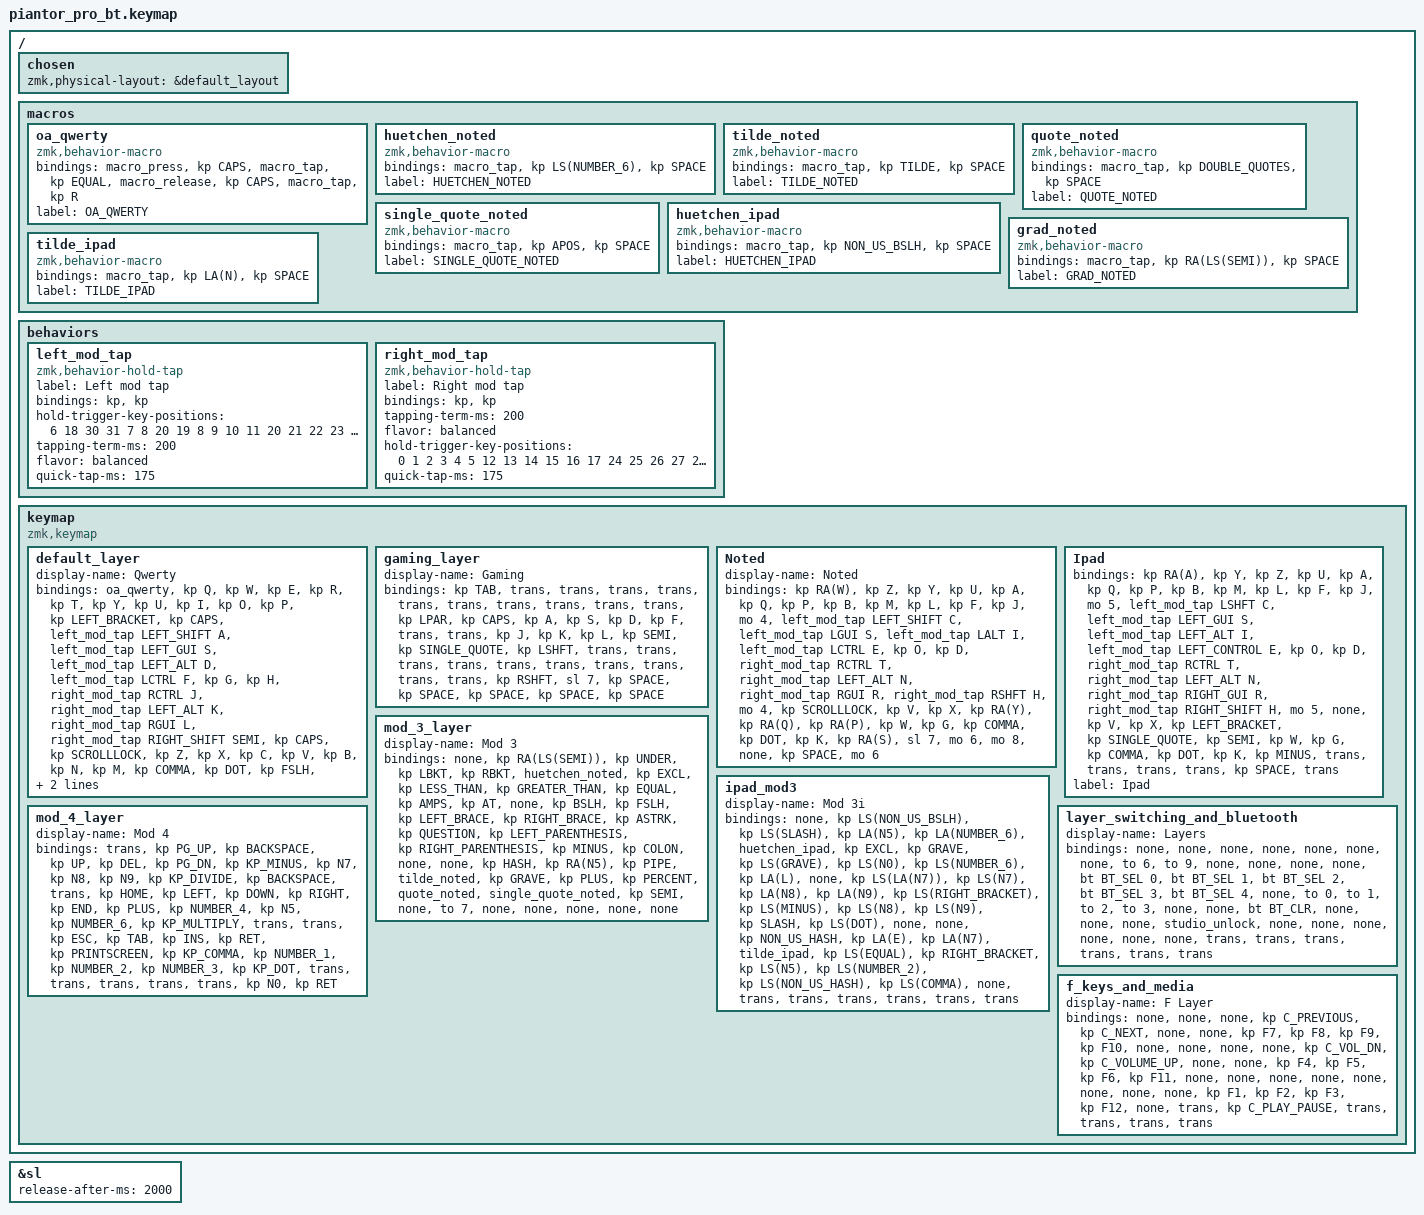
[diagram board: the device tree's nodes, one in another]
/*
 * Copyright (c) 2020 The ZMK Contributors
 *
 * SPDX-License-Identifier: MIT
 */

#include <behaviors.dtsi>
#include <dt-bindings/zmk/bt.h>
#include <dt-bindings/zmk/keys.h>

&sl {
    release-after-ms = <2000>;

    /delete-property/ quick-release;
};

/ {
    chosen { zmk,physical-layout = &default_layout; };
};

/ {
    macros {
        oa_qwerty: oa_qwerty {
            compatible = "zmk,behavior-macro";
            #binding-cells = <0>;
            bindings =
                <&macro_press>,
                <&kp CAPS>,
                <&macro_tap>,
                <&kp EQUAL>,
                <&macro_release>,
                <&kp CAPS>,
                <&macro_tap>,
                <&kp R>;

            label = "OA_QWERTY";
        };

        huetchen_noted: huetchen_noted {
            compatible = "zmk,behavior-macro";
            #binding-cells = <0>;
            bindings = <&macro_tap>, <&kp LS(NUMBER_6) &kp SPACE>;

            label = "HUETCHEN_NOTED";
        };

        tilde_noted: tilde_noted {
            compatible = "zmk,behavior-macro";
            #binding-cells = <0>;
            bindings = <&macro_tap>, <&kp TILDE &kp SPACE>;

            label = "TILDE_NOTED";
        };

        quote_noted: quote_noted {
            compatible = "zmk,behavior-macro";
            #binding-cells = <0>;
            bindings = <&macro_tap>, <&kp DOUBLE_QUOTES &kp SPACE>;

            label = "QUOTE_NOTED";
        };

        single_quote_noted: single_quote_noted {
            compatible = "zmk,behavior-macro";
            #binding-cells = <0>;
            bindings = <&macro_tap>, <&kp APOS &kp SPACE>;

            label = "SINGLE_QUOTE_NOTED";
        };

        huetchen_ipad: huetchen_ipad {
            compatible = "zmk,behavior-macro";
            #binding-cells = <0>;
            bindings = <&macro_tap>, <&kp NON_US_BSLH &kp SPACE>;

            label = "HUETCHEN_IPAD";
        };

        grad_noted: grad_noted {
            compatible = "zmk,behavior-macro";
            #binding-cells = <0>;
            bindings = <&macro_tap>, <&kp RA(LS(SEMI)) &kp SPACE>;

            label = "GRAD_NOTED";
        };

        tilde_ipad: tilde_ipad {
            compatible = "zmk,behavior-macro";
            #binding-cells = <0>;
            bindings = <&macro_tap>, <&kp LA(N) &kp SPACE>;

            label = "TILDE_IPAD";
        };
    };

    behaviors {
        left_mod_tap: left_mod_tap {
            compatible = "zmk,behavior-hold-tap";
            label = "Left mod tap";
            bindings = <&kp>, <&kp>;

            #binding-cells = <2>;
            hold-trigger-key-positions = <6 18 30 31 7 8 20 19 8 9 10 11 20 21 22 23 32 33 35 34 39 40 41 38 37 36>;
            tapping-term-ms = <200>;
            flavor = "balanced";
            quick-tap-ms = <175>;
        };

        right_mod_tap: right_mod_tap {
            compatible = "zmk,behavior-hold-tap";
            label = "Right mod tap";
            bindings = <&kp>, <&kp>;

            #binding-cells = <2>;
            tapping-term-ms = <200>;
            flavor = "balanced";
            hold-trigger-key-positions = <0 1 2 3 4 5 12 13 14 15 16 17 24 25 26 27 28 29 36 37 38 40 39 41>;
            quick-tap-ms = <175>;
        };
    };

    keymap {
        compatible = "zmk,keymap";

        default_layer {
            display-name = "Qwerty";

            // --------------------------------------------------------------------------------
            // |  TAB |  Q  |  W  |  E  |  R  |  T  |  Y  |  U   |  I  |  O  |  P  | BSPC |
            // | CTRL |  A  |  S  |  D  |  F  |  G  |  H  |  J   |  K  |  L  |  ;  |  '   |
            // | SHFT |  Z  |  X  |  C  |  V  |  B  |  N  |  M   |  ,  |  .  |  /  | ESC  |
            //                    | GUI | LWR | SPC | ENT | RSE  | ALT |

            bindings = <
&oa_qwerty  &kp Q  &kp W  &kp E  &kp R  &kp T  &kp Y  &kp U  &kp I  &kp O  &kp P  &kp LEFT_BRACKET  &kp CAPS  &left_mod_tap LEFT_SHIFT A  &left_mod_tap LEFT_GUI S  &left_mod_tap LEFT_ALT D  &left_mod_tap LCTRL F  &kp G  &kp H  &right_mod_tap RCTRL J  &right_mod_tap LEFT_ALT K  &right_mod_tap RGUI L  &right_mod_tap RIGHT_SHIFT SEMI  &kp CAPS  &kp SCROLLLOCK  &kp Z  &kp X  &kp C  &kp V  &kp B  &kp N  &kp M  &kp COMMA  &kp DOT  &kp FSLH  &kp RIGHT_BRACKET  &sl 7  &mo 6  &mo 8  &none  &kp SPACE  &mo 6
            >;
        };

        gaming_layer {
            display-name = "Gaming";
            bindings = <
&kp TAB  &trans  &trans  &trans  &trans  &trans  &trans  &trans  &trans  &trans  &trans  &kp LPAR  &kp CAPS  &kp A  &kp S  &kp D  &kp F  &trans  &trans  &kp J  &kp K  &kp L  &kp SEMI  &kp SINGLE_QUOTE  &kp LSHFT  &trans  &trans  &trans  &trans  &trans  &trans  &trans  &trans  &trans  &trans  &kp RSHFT  &sl 7  &kp SPACE  &kp SPACE  &kp SPACE  &kp SPACE  &kp SPACE
            >;
        };

        Noted {
            display-name = "Noted";
            bindings = <
&kp RA(W)  &kp Z  &kp Y  &kp U  &kp A  &kp Q  &kp P  &kp B  &kp M  &kp L  &kp F  &kp J  &mo 4  &left_mod_tap LEFT_SHIFT C  &left_mod_tap LGUI S  &left_mod_tap LALT I  &left_mod_tap LCTRL E  &kp O  &kp D  &right_mod_tap RCTRL T  &right_mod_tap LEFT_ALT N  &right_mod_tap RGUI R  &right_mod_tap RSHFT H  &mo 4  &kp SCROLLLOCK  &kp V  &kp X  &kp RA(Y)  &kp RA(Q)  &kp RA(P)  &kp W  &kp G  &kp COMMA  &kp DOT  &kp K  &kp RA(S)  &sl 7  &mo 6  &mo 8  &none  &kp SPACE  &mo 6
            >;
        };

        Ipad {
            bindings = <
&kp RA(A)  &kp Y  &kp Z  &kp U  &kp A  &kp Q  &kp P  &kp B  &kp M  &kp L  &kp F  &kp J  &mo 5  &left_mod_tap LSHFT C  &left_mod_tap LEFT_GUI S  &left_mod_tap LEFT_ALT I  &left_mod_tap LEFT_CONTROL E  &kp O  &kp D  &right_mod_tap RCTRL T  &right_mod_tap LEFT_ALT N  &right_mod_tap RIGHT_GUI R  &right_mod_tap RIGHT_SHIFT H  &mo 5  &none  &kp V  &kp X  &kp LEFT_BRACKET  &kp SINGLE_QUOTE  &kp SEMI  &kp W  &kp G  &kp COMMA  &kp DOT  &kp K  &kp MINUS  &trans  &trans  &trans  &trans  &kp SPACE  &trans
            >;

            label = "Ipad";
        };

        mod_3_layer {
            display-name = "Mod 3";
            bindings = <
&none  &kp RA(LS(SEMI))  &kp UNDER  &kp LBKT  &kp RBKT  &huetchen_noted  &kp EXCL  &kp LESS_THAN  &kp GREATER_THAN  &kp EQUAL  &kp AMPS  &kp AT  &none  &kp BSLH  &kp FSLH  &kp LEFT_BRACE  &kp RIGHT_BRACE  &kp ASTRK  &kp QUESTION  &kp LEFT_PARENTHESIS  &kp RIGHT_PARENTHESIS  &kp MINUS  &kp COLON  &none  &none  &kp HASH  &kp RA(N5)  &kp PIPE  &tilde_noted  &kp GRAVE  &kp PLUS  &kp PERCENT  &quote_noted  &single_quote_noted  &kp SEMI  &none  &to 7  &none  &none  &none  &none  &none
            >;
        };

        ipad_mod3 {
            display-name = "Mod 3i";
            bindings = <
&none  &kp LS(NON_US_BSLH)  &kp LS(SLASH)  &kp LA(N5)  &kp LA(NUMBER_6)  &huetchen_ipad  &kp EXCL  &kp GRAVE  &kp LS(GRAVE)  &kp LS(N0)  &kp LS(NUMBER_6)  &kp LA(L)  &none  &kp LS(LA(N7))  &kp LS(N7)  &kp LA(N8)  &kp LA(N9)  &kp LS(RIGHT_BRACKET)  &kp LS(MINUS)  &kp LS(N8)  &kp LS(N9)  &kp SLASH  &kp LS(DOT)  &none  &none  &kp NON_US_HASH  &kp LA(E)  &kp LA(N7)  &tilde_ipad  &kp LS(EQUAL)  &kp RIGHT_BRACKET  &kp LS(N5)  &kp LS(NUMBER_2)  &kp LS(NON_US_HASH)  &kp LS(COMMA)  &none  &trans  &trans  &trans  &trans  &trans  &trans
            >;
        };

        mod_4_layer {
            display-name = "Mod 4";

            // -----------------------------------------------------------------------------------------
            // |  TAB |  1  |  2  |  3  |  4  |  5    |  6  |  7  |  8  |  9  |  0  | BSPC |
            // | CTRL | BT1 | BT2 | BT3 | BT4 | BT5   | LFT | DWN |  UP | RGT |     |      |
            // | SHFT | BTCR| RGB | RST | BOOT| Unlock|     |     |     |     |     |      |
            //                    | GUI |     | SPC   | ENT |     | ALT |

            bindings = <
&trans  &kp PG_UP  &kp BACKSPACE  &kp UP  &kp DEL  &kp PG_DN  &kp KP_MINUS  &kp N7  &kp N8  &kp N9  &kp KP_DIVIDE  &kp BACKSPACE  &trans  &kp HOME  &kp LEFT  &kp DOWN  &kp RIGHT  &kp END  &kp PLUS  &kp NUMBER_4  &kp N5  &kp NUMBER_6  &kp KP_MULTIPLY  &trans  &trans  &kp ESC  &kp TAB  &kp INS  &kp RET  &kp PRINTSCREEN  &kp KP_COMMA  &kp NUMBER_1  &kp NUMBER_2  &kp NUMBER_3  &kp KP_DOT  &trans  &trans  &trans  &trans  &trans  &kp N0  &kp RET
            >;
        };

        layer_switching_and_bluetooth {
            display-name = "Layers";
            bindings = <
&none  &none  &none  &none  &none  &none  &none  &to 6  &to 9  &none  &none  &none  &none  &bt BT_SEL 0  &bt BT_SEL 1  &bt BT_SEL 2  &bt BT_SEL 3  &bt BT_SEL 4  &none  &to 0  &to 1  &to 2  &to 3  &none  &none  &bt BT_CLR  &none  &none  &none  &studio_unlock  &none  &none  &none  &none  &none  &none  &trans  &trans  &trans  &trans  &trans  &trans
            >;
        };

        f_keys_and_media {
            display-name = "F Layer";
            bindings = <
&none  &none  &none  &kp C_PREVIOUS  &kp C_NEXT  &none  &none  &kp F7  &kp F8  &kp F9  &kp F10  &none  &none  &none  &none  &kp C_VOL_DN  &kp C_VOLUME_UP  &none  &none  &kp F4  &kp F5  &kp F6  &kp F11  &none  &none  &none  &none  &none  &none  &none  &none  &kp F1  &kp F2  &kp F3  &kp F12  &none  &trans  &kp C_PLAY_PAUSE  &trans  &trans  &trans  &trans
            >;
        };
    };
};
